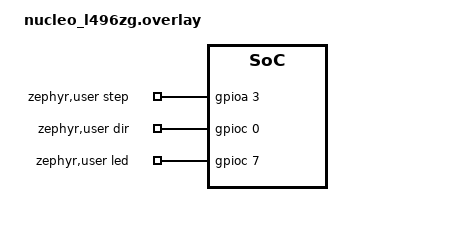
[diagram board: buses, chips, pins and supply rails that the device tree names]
#include <zephyr/dt-bindings/gpio/gpio.h>

/ {
     zephyr,user {
             step-gpios = <&gpioa 3 GPIO_ACTIVE_HIGH>;
             dir-gpios = <&gpioc 0 GPIO_ACTIVE_HIGH>;
             led-gpios = <&gpioc 7 GPIO_ACTIVE_HIGH>;
     };
};
